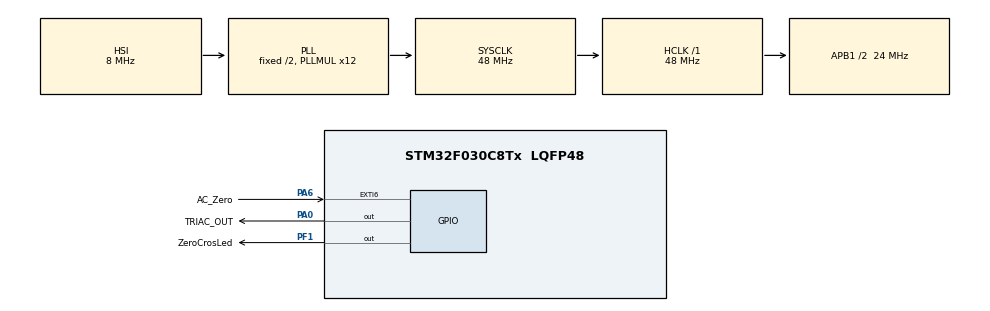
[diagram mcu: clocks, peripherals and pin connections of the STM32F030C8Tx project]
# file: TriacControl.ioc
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Mcu.Family=STM32F0
Mcu.Name=STM32F030C8Tx
Mcu.Package=LQFP48
NVIC.EXTI4_15_IRQn=true\:0\:0\:false\:false\:true\:true\:true\:true
NVIC.TIM1_BRK_UP_TRG_COM_IRQn=true\:0\:0\:false\:false\:true\:true\:true\:true
NVIC.TIM1_CC_IRQn=true\:0\:0\:false\:false\:true\:true\:true\:true
PA0.GPIO_Label=TRIAC_OUT
PA0.Signal=GPIO_Output
PA13.Mode=Serial_Wire
PA13.Signal=SYS_SWDIO
PA14.Mode=Serial_Wire
PA14.Signal=SYS_SWCLK
PA6.GPIO_Label=AC_Zero
PA6.GPIO_ModeDefaultEXTI=GPIO_MODE_IT_RISING_FALLING
PA6.Signal=GPXTI6
PF1-OSC_OUT.GPIO_Label=ZeroCrosLed
PF1-OSC_OUT.Signal=GPIO_Output
ProjectManager.HeapSize=0x200
ProjectManager.StackSize=0x400
ProjectManager.TargetToolchain=STM32CubeIDE
RCC.AHBFreq_Value=48000000
RCC.APB1CLKDivider=RCC_HCLK_DIV2
RCC.APB1Freq_Value=24000000
RCC.APB1TimFreq_Value=48000000
RCC.HCLKFreq_Value=48000000
RCC.PLLMUL=RCC_PLL_MUL12
RCC.SYSCLKFreq_VALUE=48000000
RCC.SYSCLKSource=RCC_SYSCLKSOURCE_PLLCLK
RCC.VDD_VALUE=3.3
TIM1.AutoReloadPreload=TIM_AUTORELOAD_PRELOAD_DISABLE
TIM1.AutomaticOutput=TIM_AUTOMATICOUTPUT_ENABLE
TIM1.BreakState=TIM_BREAK_ENABLE
TIM1.Channel-Output\ Compare1\ No\ Output=TIM_CHANNEL_1
TIM1.Channel-Output\ Compare2\ No\ Output=TIM_CHANNEL_2
TIM1.CounterMode=TIM_COUNTERMODE_UP
TIM1.LockLevel=TIM_LOCKLEVEL_1
TIM1.OCMode_1=TIM_OCMODE_TIMING
TIM1.OCMode_2=TIM_OCMODE_TIMING
TIM1.OffStateIDLEMode=TIM_OSSI_ENABLE
TIM1.OffStateRunMode=TIM_OSSR_ENABLE
TIM1.Period=65535
TIM1.Prescaler=360-1
TIM1.Pulse-Output\ Compare1\ No\ Output=1000
TIM1.Pulse-Output\ Compare2\ No\ Output=1100
TIM1.TIM_MasterOutputTrigger=TIM_TRGO_RESET
VP_TIM1_VS_no_output1.Mode=Output Compare1 No Output
VP_TIM1_VS_no_output2.Mode=Output Compare2 No Output
board=custom

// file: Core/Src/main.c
/* USER CODE BEGIN Header */
/**
  ******************************************************************************
  * @file           : main.c
  * @brief          : Main program body
  ******************************************************************************
  * @attention
  *
  * Copyright (c) 2024 STMicroelectronics.
  * All rights reserved.
  *
  * This software is licensed under terms that can be found in the LICENSE file
  * in the root directory of this software component.
  * If no LICENSE file comes with this software, it is provided AS-IS.
  *
  ******************************************************************************
  */
/* USER CODE END Header */
#include "main.h"

TIM_HandleTypeDef htim1;

/* USER CODE BEGIN PV */
uint32_t TriacValue = 0;
/* USER CODE END PV */

void SystemClock_Config(void);
static void MX_GPIO_Init(void);
static void MX_TIM1_Init(void);

/* USER CODE BEGIN 0 */

void HAL_GPIO_EXTI_Callback(uint16_t GPIO_Pin) {
	static uint8_t Flag = 0;
	if (GPIO_Pin == AC_Zero_Pin){
		  if(HAL_GPIO_ReadPin(AC_Zero_GPIO_Port, AC_Zero_Pin) == 1){
			  HAL_GPIO_WritePin(ZeroCrosLed_GPIO_Port,ZeroCrosLed_Pin,1);
			  if (Flag == 0){
				  TIM1->CNT =0;
				  Flag=1;
			  }
		  }else{
			  HAL_GPIO_WritePin(ZeroCrosLed_GPIO_Port,ZeroCrosLed_Pin,0);
			  Flag=0;

		  }
	}
}

void HAL_TIM_OC_DelayElapsedCallback(TIM_HandleTypeDef *htim){
	if (htim == &htim1 && htim->Channel == HAL_TIM_ACTIVE_CHANNEL_1){
		HAL_GPIO_WritePin(TRIAC_OUT_GPIO_Port,TRIAC_OUT_Pin,0);
	} else if (htim == &htim1 && htim->Channel == HAL_TIM_ACTIVE_CHANNEL_2){
		HAL_GPIO_WritePin(TRIAC_OUT_GPIO_Port,TRIAC_OUT_Pin,1);
		TIM1->CCR2 = TriacValue + 100;
		TIM1->CCR1 = TriacValue ;
	}
}

/*
 * val : max -> 1200 , min ->  0
 */
void TriacControlSet(uint32_t val) {
	TriacValue = val;
}

/* USER CODE END 0 */

int main(void)
{

  /* MCU Configuration--------------------------------------------------------*/

  /* Reset of all peripherals, Initializes the Flash interface and the Systick. */
  HAL_Init();

  /* Configure the system clock */
  SystemClock_Config();

  /* Initialize all configured peripherals */
  MX_GPIO_Init();
  MX_TIM1_Init();
  /* USER CODE BEGIN 2 */
	HAL_TIMEx_OCN_Start_IT(&htim1, TIM_CHANNEL_1);
	HAL_TIMEx_OCN_Start_IT(&htim1, TIM_CHANNEL_2);
	HAL_TIM_Base_Start_IT(&htim1);
  /* USER CODE END 2 */

  /* Infinite loop */
  /* USER CODE BEGIN WHILE */
  while (1)
  {
	  TriacControlSet(800);
	  HAL_Delay(5000);
	  TriacControlSet(300);
	  HAL_Delay(5000);
    /* USER CODE END WHILE */

  }
}

void SystemClock_Config(void)
{
  RCC_OscInitTypeDef RCC_OscInitStruct = {0};
  RCC_ClkInitTypeDef RCC_ClkInitStruct = {0};

  /** Initializes the RCC Oscillators according to the specified parameters
  * in the RCC_OscInitTypeDef structure.
  */
  RCC_OscInitStruct.OscillatorType = RCC_OSCILLATORTYPE_HSI;
  RCC_OscInitStruct.HSIState = RCC_HSI_ON;
  RCC_OscInitStruct.HSICalibrationValue = RCC_HSICALIBRATION_DEFAULT;
  RCC_OscInitStruct.PLL.PLLState = RCC_PLL_ON;
  RCC_OscInitStruct.PLL.PLLSource = RCC_PLLSOURCE_HSI;
  RCC_OscInitStruct.PLL.PLLMUL = RCC_PLL_MUL12;
  RCC_OscInitStruct.PLL.PREDIV = RCC_PREDIV_DIV1;
  if (HAL_RCC_OscConfig(&RCC_OscInitStruct) != HAL_OK)
  {
    Error_Handler();
  }

  /** Initializes the CPU, AHB and APB buses clocks
  */
  RCC_ClkInitStruct.ClockType = RCC_CLOCKTYPE_HCLK|RCC_CLOCKTYPE_SYSCLK
                              |RCC_CLOCKTYPE_PCLK1;
  RCC_ClkInitStruct.SYSCLKSource = RCC_SYSCLKSOURCE_PLLCLK;
  RCC_ClkInitStruct.AHBCLKDivider = RCC_SYSCLK_DIV1;
  RCC_ClkInitStruct.APB1CLKDivider = RCC_HCLK_DIV2;

  if (HAL_RCC_ClockConfig(&RCC_ClkInitStruct, FLASH_LATENCY_1) != HAL_OK)
  {
    Error_Handler();
  }
}

static void MX_TIM1_Init(void)
{

  TIM_MasterConfigTypeDef sMasterConfig = {0};
  TIM_OC_InitTypeDef sConfigOC = {0};
  TIM_BreakDeadTimeConfigTypeDef sBreakDeadTimeConfig = {0};

  htim1.Instance = TIM1;
  htim1.Init.Prescaler = 360-1;
  htim1.Init.CounterMode = TIM_COUNTERMODE_UP;
  htim1.Init.Period = 65535;
  htim1.Init.ClockDivision = TIM_CLOCKDIVISION_DIV1;
  htim1.Init.RepetitionCounter = 0;
  htim1.Init.AutoReloadPreload = TIM_AUTORELOAD_PRELOAD_DISABLE;
  if (HAL_TIM_OC_Init(&htim1) != HAL_OK)
  {
    Error_Handler();
  }
  sMasterConfig.MasterOutputTrigger = TIM_TRGO_RESET;
  sMasterConfig.MasterSlaveMode = TIM_MASTERSLAVEMODE_DISABLE;
  if (HAL_TIMEx_MasterConfigSynchronization(&htim1, &sMasterConfig) != HAL_OK)
  {
    Error_Handler();
  }
  sConfigOC.OCMode = TIM_OCMODE_TIMING;
  sConfigOC.Pulse = 1000;
  sConfigOC.OCPolarity = TIM_OCPOLARITY_HIGH;
  sConfigOC.OCNPolarity = TIM_OCNPOLARITY_HIGH;
  sConfigOC.OCFastMode = TIM_OCFAST_DISABLE;
  sConfigOC.OCIdleState = TIM_OCIDLESTATE_RESET;
  sConfigOC.OCNIdleState = TIM_OCNIDLESTATE_RESET;
  if (HAL_TIM_OC_ConfigChannel(&htim1, &sConfigOC, TIM_CHANNEL_1) != HAL_OK)
  {
    Error_Handler();
  }
  sConfigOC.Pulse = 1100;
  if (HAL_TIM_OC_ConfigChannel(&htim1, &sConfigOC, TIM_CHANNEL_2) != HAL_OK)
  {
    Error_Handler();
  }
  sBreakDeadTimeConfig.OffStateRunMode = TIM_OSSR_ENABLE;
  sBreakDeadTimeConfig.OffStateIDLEMode = TIM_OSSI_ENABLE;
  sBreakDeadTimeConfig.LockLevel = TIM_LOCKLEVEL_1;
  sBreakDeadTimeConfig.DeadTime = 0;
  sBreakDeadTimeConfig.BreakState = TIM_BREAK_ENABLE;
  sBreakDeadTimeConfig.BreakPolarity = TIM_BREAKPOLARITY_HIGH;
  sBreakDeadTimeConfig.AutomaticOutput = TIM_AUTOMATICOUTPUT_ENABLE;
  if (HAL_TIMEx_ConfigBreakDeadTime(&htim1, &sBreakDeadTimeConfig) != HAL_OK)
  {
    Error_Handler();
  }

}

static void MX_GPIO_Init(void)
{
  GPIO_InitTypeDef GPIO_InitStruct = {0};

  /* GPIO Ports Clock Enable */
  __HAL_RCC_GPIOF_CLK_ENABLE();
  __HAL_RCC_GPIOA_CLK_ENABLE();

  /*Configure GPIO pin Output Level */
  HAL_GPIO_WritePin(ZeroCrosLed_GPIO_Port, ZeroCrosLed_Pin, GPIO_PIN_RESET);

  /*Configure GPIO pin Output Level */
  HAL_GPIO_WritePin(TRIAC_OUT_GPIO_Port, TRIAC_OUT_Pin, GPIO_PIN_RESET);

  /*Configure GPIO pin : ZeroCrosLed_Pin */
  GPIO_InitStruct.Pin = ZeroCrosLed_Pin;
  GPIO_InitStruct.Mode = GPIO_MODE_OUTPUT_PP;
  GPIO_InitStruct.Pull = GPIO_NOPULL;
  GPIO_InitStruct.Speed = GPIO_SPEED_FREQ_LOW;
  HAL_GPIO_Init(ZeroCrosLed_GPIO_Port, &GPIO_InitStruct);

  /*Configure GPIO pin : TRIAC_OUT_Pin */
  GPIO_InitStruct.Pin = TRIAC_OUT_Pin;
  GPIO_InitStruct.Mode = GPIO_MODE_OUTPUT_PP;
  GPIO_InitStruct.Pull = GPIO_NOPULL;
  GPIO_InitStruct.Speed = GPIO_SPEED_FREQ_LOW;
  HAL_GPIO_Init(TRIAC_OUT_GPIO_Port, &GPIO_InitStruct);

  /*Configure GPIO pin : AC_Zero_Pin */
  GPIO_InitStruct.Pin = AC_Zero_Pin;
  GPIO_InitStruct.Mode = GPIO_MODE_IT_RISING_FALLING;
  GPIO_InitStruct.Pull = GPIO_NOPULL;
  HAL_GPIO_Init(AC_Zero_GPIO_Port, &GPIO_InitStruct);

  /* EXTI interrupt init*/
  HAL_NVIC_SetPriority(EXTI4_15_IRQn, 0, 0);
  HAL_NVIC_EnableIRQ(EXTI4_15_IRQn);

}

void Error_Handler(void)
{
  __disable_irq();
  while (1)
  {
  }
}
